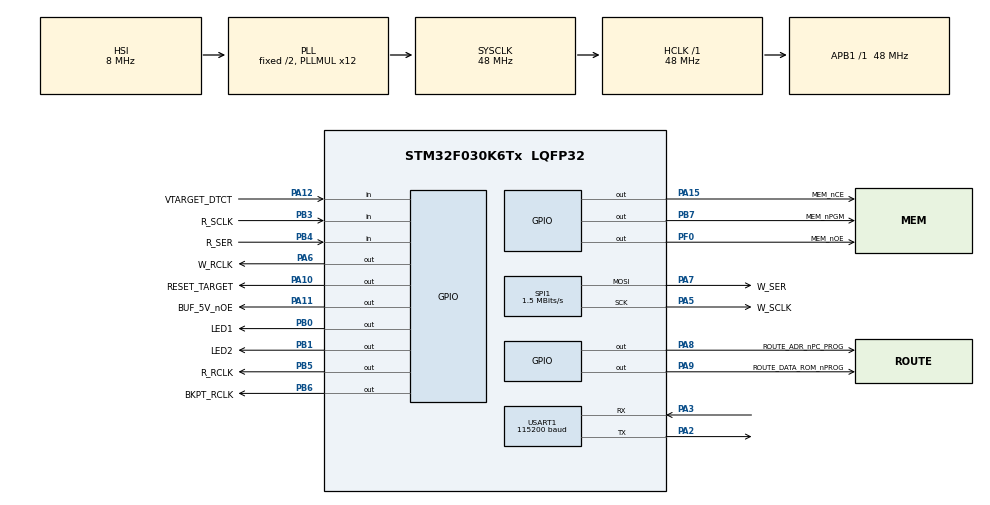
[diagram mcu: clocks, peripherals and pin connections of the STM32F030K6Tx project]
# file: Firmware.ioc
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Mcu.Family=STM32F0
TIM17.Prescaler=48
VP_TIM17_VS_ClockSourceINT.Mode=Enable_Timer
PA7.Mode=TX_Only_Simplex_Unidirect_Master
SPI1.VirtualType=VM_MASTER
USART1.BaudRate=115200
PA9.GPIO_Label=ROUTE_DATA_ROM_nPROG
PA11.GPIO_Label=BUF_5V_nOE
PA6.GPIO_Label=W_RCLK
PB0.GPIO_Label=LED1
PB6.GPIO_Label=BKPT_RCLK
PA12.GPIO_Label=VTARGET_DTCT
RCC.SYSCLKSource=RCC_SYSCLKSOURCE_PLLCLK
ProjectManager.StackSize=0x400
USART1.VirtualMode-Asynchronous=VM_ASYNC
PA3.Mode=Asynchronous
PA13.Signal=SYS_SWDIO
PA15.GPIO_Label=MEM_nCE
PA12.Signal=GPIO_Input
PA8.GPIO_Label=ROUTE_ADR_nPC_PROG
ProjectManager.TargetToolchain=STM32CubeIDE
SPI1.Direction=SPI_DIRECTION_2LINES
RCC.HCLKFreq_Value=48000000
PA9.Signal=GPIO_Output
PB6.Signal=GPIO_Output
SPI1.CalculateBaudRate=1.5 MBits/s
RCC.AHBFreq_Value=48000000
PA5.Signal=SPI1_SCK
PF0-OSC_IN.GPIO_Label=MEM_nOE
board=custom
RCC.PLLMUL=RCC_PLL_MUL12
PB4.GPIO_Label=R_SER
SPI1.Mode=SPI_MODE_MASTER
PA14.Mode=Serial_Wire
PB1.GPIO_Label=LED2
SPI1.DataSize=SPI_DATASIZE_8BIT
PA10.GPIO_Label=RESET_TARGET
PB7.Signal=GPIO_Output
PA8.Signal=GPIO_Output
PA13.Mode=Serial_Wire
Mcu.Name=STM32F030K6Tx
PA2.Signal=USART1_TX
PB7.GPIO_Label=MEM_nPGM
PB3.Signal=GPIO_Input
RCC.SYSCLKFreq_VALUE=48000000
Mcu.Package=LQFP32
PB5.Signal=GPIO_Output
PA6.Signal=GPIO_Output
PB1.Signal=GPIO_Output
PA7.GPIO_Label=W_SER
PA5.GPIO_Label=W_SCLK
PA11.Signal=GPIO_Output
PA10.Signal=GPIO_Output
PA14.Signal=SYS_SWCLK
PA15.Signal=GPIO_Output
ProjectManager.HeapSize=0x200
PB5.GPIO_Label=R_RCLK
RCC.APB1TimFreq_Value=48000000
PA2.Mode=Asynchronous
PF0-OSC_IN.Signal=GPIO_Output
PA11.PinState=GPIO_PIN_SET
RCC.APB1Freq_Value=48000000
SPI1.BaudRatePrescaler=SPI_BAUDRATEPRESCALER_32
PB0.Signal=GPIO_Output
PB4.Signal=GPIO_Input
PA3.Signal=USART1_RX
PA7.Signal=SPI1_MOSI
PA5.Mode=TX_Only_Simplex_Unidirect_Master
PB3.GPIO_Label=R_SCLK

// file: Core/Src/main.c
/* USER CODE BEGIN Header */
/**
 ******************************************************************************
 * @file           : main.c
 * @brief          : Main program body
 ******************************************************************************
 * @attention
 *
 * <h2><center>&copy; Copyright (c) 2021 STMicroelectronics.
 * All rights reserved.</center></h2>
 *
 * This software component is licensed by ST under BSD 3-Clause license,
 * the "License"; You may not use this file except in compliance with the
 * License. You may obtain a copy of the License at:
 *                        opensource.org/licenses/BSD-3-Clause
 *
 ******************************************************************************
 */
/* USER CODE END Header */
#include "main.h"

/* USER CODE BEGIN Includes */
#include "psPROG.h"
/* USER CODE END Includes */

SPI_HandleTypeDef hspi1;

TIM_HandleTypeDef htim17;

UART_HandleTypeDef huart1;

void SystemClock_Config(void);
static void MX_GPIO_Init(void);
static void MX_SPI1_Init(void);
static void MX_USART1_UART_Init(void);
static void MX_TIM17_Init(void);

int main(void)
{

  /* MCU Configuration--------------------------------------------------------*/

  /* Reset of all peripherals, Initializes the Flash interface and the Systick. */
  HAL_Init();

  /* Configure the system clock */
  SystemClock_Config();

  /* Initialize all configured peripherals */
  MX_GPIO_Init();
  MX_SPI1_Init();
  MX_USART1_UART_Init();
  MX_TIM17_Init();

  /* Infinite loop */
  /* USER CODE BEGIN WHILE */

  psPROG(); // Never returns

  while (1) {
    /* USER CODE END WHILE */

  }
}

void SystemClock_Config(void)
{
  RCC_OscInitTypeDef RCC_OscInitStruct = {0};
  RCC_ClkInitTypeDef RCC_ClkInitStruct = {0};
  RCC_PeriphCLKInitTypeDef PeriphClkInit = {0};

  /** Initializes the RCC Oscillators according to the specified parameters
  * in the RCC_OscInitTypeDef structure.
  */
  RCC_OscInitStruct.OscillatorType = RCC_OSCILLATORTYPE_HSI;
  RCC_OscInitStruct.HSIState = RCC_HSI_ON;
  RCC_OscInitStruct.HSICalibrationValue = RCC_HSICALIBRATION_DEFAULT;
  RCC_OscInitStruct.PLL.PLLState = RCC_PLL_ON;
  RCC_OscInitStruct.PLL.PLLSource = RCC_PLLSOURCE_HSI;
  RCC_OscInitStruct.PLL.PLLMUL = RCC_PLL_MUL12;
  RCC_OscInitStruct.PLL.PREDIV = RCC_PREDIV_DIV1;
  if (HAL_RCC_OscConfig(&RCC_OscInitStruct) != HAL_OK)
  {
    Error_Handler();
  }
  /** Initializes the CPU, AHB and APB buses clocks
  */
  RCC_ClkInitStruct.ClockType = RCC_CLOCKTYPE_HCLK|RCC_CLOCKTYPE_SYSCLK
                              |RCC_CLOCKTYPE_PCLK1;
  RCC_ClkInitStruct.SYSCLKSource = RCC_SYSCLKSOURCE_PLLCLK;
  RCC_ClkInitStruct.AHBCLKDivider = RCC_SYSCLK_DIV1;
  RCC_ClkInitStruct.APB1CLKDivider = RCC_HCLK_DIV1;

  if (HAL_RCC_ClockConfig(&RCC_ClkInitStruct, FLASH_LATENCY_1) != HAL_OK)
  {
    Error_Handler();
  }
  PeriphClkInit.PeriphClockSelection = RCC_PERIPHCLK_USART1;
  PeriphClkInit.Usart1ClockSelection = RCC_USART1CLKSOURCE_PCLK1;
  if (HAL_RCCEx_PeriphCLKConfig(&PeriphClkInit) != HAL_OK)
  {
    Error_Handler();
  }
}

static void MX_SPI1_Init(void)
{

  /* SPI1 parameter configuration*/
  hspi1.Instance = SPI1;
  hspi1.Init.Mode = SPI_MODE_MASTER;
  hspi1.Init.Direction = SPI_DIRECTION_2LINES;
  hspi1.Init.DataSize = SPI_DATASIZE_8BIT;
  hspi1.Init.CLKPolarity = SPI_POLARITY_LOW;
  hspi1.Init.CLKPhase = SPI_PHASE_1EDGE;
  hspi1.Init.NSS = SPI_NSS_SOFT;
  hspi1.Init.BaudRatePrescaler = SPI_BAUDRATEPRESCALER_32;
  hspi1.Init.FirstBit = SPI_FIRSTBIT_MSB;
  hspi1.Init.TIMode = SPI_TIMODE_DISABLE;
  hspi1.Init.CRCCalculation = SPI_CRCCALCULATION_DISABLE;
  hspi1.Init.CRCPolynomial = 7;
  hspi1.Init.CRCLength = SPI_CRC_LENGTH_DATASIZE;
  hspi1.Init.NSSPMode = SPI_NSS_PULSE_ENABLE;
  if (HAL_SPI_Init(&hspi1) != HAL_OK)
  {
    Error_Handler();
  }

}

static void MX_TIM17_Init(void)
{

  htim17.Instance = TIM17;
  htim17.Init.Prescaler = 48;
  htim17.Init.CounterMode = TIM_COUNTERMODE_UP;
  htim17.Init.Period = 65535;
  htim17.Init.ClockDivision = TIM_CLOCKDIVISION_DIV1;
  htim17.Init.RepetitionCounter = 0;
  htim17.Init.AutoReloadPreload = TIM_AUTORELOAD_PRELOAD_DISABLE;
  if (HAL_TIM_Base_Init(&htim17) != HAL_OK)
  {
    Error_Handler();
  }
  /* USER CODE BEGIN TIM17_Init 2 */
  HAL_TIM_Base_Start(&htim17);

  /* USER CODE END TIM17_Init 2 */

}

static void MX_USART1_UART_Init(void)
{

  huart1.Instance = USART1;
  huart1.Init.BaudRate = 115200;
  huart1.Init.WordLength = UART_WORDLENGTH_8B;
  huart1.Init.StopBits = UART_STOPBITS_1;
  huart1.Init.Parity = UART_PARITY_NONE;
  huart1.Init.Mode = UART_MODE_TX_RX;
  huart1.Init.HwFlowCtl = UART_HWCONTROL_NONE;
  huart1.Init.OverSampling = UART_OVERSAMPLING_16;
  huart1.Init.OneBitSampling = UART_ONE_BIT_SAMPLE_DISABLE;
  huart1.AdvancedInit.AdvFeatureInit = UART_ADVFEATURE_NO_INIT;
  if (HAL_UART_Init(&huart1) != HAL_OK)
  {
    Error_Handler();
  }

}

static void MX_GPIO_Init(void)
{
  GPIO_InitTypeDef GPIO_InitStruct = {0};

  /* GPIO Ports Clock Enable */
  __HAL_RCC_GPIOF_CLK_ENABLE();
  __HAL_RCC_GPIOA_CLK_ENABLE();
  __HAL_RCC_GPIOB_CLK_ENABLE();

  /*Configure GPIO pin Output Level */
  HAL_GPIO_WritePin(MEM_nOE_GPIO_Port, MEM_nOE_Pin, GPIO_PIN_RESET);

  /*Configure GPIO pin Output Level */
  HAL_GPIO_WritePin(GPIOA, W_RCLK_Pin|ROUTE_ADR_nPC_PROG_Pin|ROUTE_DATA_ROM_nPROG_Pin|RESET_TARGET_Pin
                          |MEM_nCE_Pin, GPIO_PIN_RESET);

  /*Configure GPIO pin Output Level */
  HAL_GPIO_WritePin(GPIOB, LED1_Pin|LED2_Pin|R_RCLK_Pin|BKPT_RCLK_Pin
                          |MEM_nPGM_Pin, GPIO_PIN_RESET);

  /*Configure GPIO pin Output Level */
  HAL_GPIO_WritePin(BUF_5V_nOE_GPIO_Port, BUF_5V_nOE_Pin, GPIO_PIN_SET);

  /*Configure GPIO pin : MEM_nOE_Pin */
  GPIO_InitStruct.Pin = MEM_nOE_Pin;
  GPIO_InitStruct.Mode = GPIO_MODE_OUTPUT_PP;
  GPIO_InitStruct.Pull = GPIO_NOPULL;
  GPIO_InitStruct.Speed = GPIO_SPEED_FREQ_LOW;
  HAL_GPIO_Init(MEM_nOE_GPIO_Port, &GPIO_InitStruct);

  /*Configure GPIO pins : W_RCLK_Pin ROUTE_ADR_nPC_PROG_Pin ROUTE_DATA_ROM_nPROG_Pin RESET_TARGET_Pin
                           BUF_5V_nOE_Pin MEM_nCE_Pin */
  GPIO_InitStruct.Pin = W_RCLK_Pin|ROUTE_ADR_nPC_PROG_Pin|ROUTE_DATA_ROM_nPROG_Pin|RESET_TARGET_Pin
                          |BUF_5V_nOE_Pin|MEM_nCE_Pin;
  GPIO_InitStruct.Mode = GPIO_MODE_OUTPUT_PP;
  GPIO_InitStruct.Pull = GPIO_NOPULL;
  GPIO_InitStruct.Speed = GPIO_SPEED_FREQ_LOW;
  HAL_GPIO_Init(GPIOA, &GPIO_InitStruct);

  /*Configure GPIO pins : LED1_Pin LED2_Pin R_RCLK_Pin BKPT_RCLK_Pin
                           MEM_nPGM_Pin */
  GPIO_InitStruct.Pin = LED1_Pin|LED2_Pin|R_RCLK_Pin|BKPT_RCLK_Pin
                          |MEM_nPGM_Pin;
  GPIO_InitStruct.Mode = GPIO_MODE_OUTPUT_PP;
  GPIO_InitStruct.Pull = GPIO_NOPULL;
  GPIO_InitStruct.Speed = GPIO_SPEED_FREQ_LOW;
  HAL_GPIO_Init(GPIOB, &GPIO_InitStruct);

  /*Configure GPIO pin : VTARGET_DTCT_Pin */
  GPIO_InitStruct.Pin = VTARGET_DTCT_Pin;
  GPIO_InitStruct.Mode = GPIO_MODE_INPUT;
  GPIO_InitStruct.Pull = GPIO_NOPULL;
  HAL_GPIO_Init(VTARGET_DTCT_GPIO_Port, &GPIO_InitStruct);

  /*Configure GPIO pins : R_SCLK_Pin R_SER_Pin */
  GPIO_InitStruct.Pin = R_SCLK_Pin|R_SER_Pin;
  GPIO_InitStruct.Mode = GPIO_MODE_INPUT;
  GPIO_InitStruct.Pull = GPIO_NOPULL;
  HAL_GPIO_Init(GPIOB, &GPIO_InitStruct);

}

void Error_Handler(void)
{
  __disable_irq();
  while (1) {
  }
}

#ifdef  USE_FULL_ASSERT
/**
  * @brief  Reports the name of the source file and the source line number
  *         where the assert_param error has occurred.
  * @param  file: pointer to the source file name
  * @param  line: assert_param error line source number
  * @retval None
  */
void assert_failed(uint8_t *file, uint32_t line)
{
  /* USER CODE BEGIN 6 */
  /* User can add his own implementation to report the file name and line
     number,
     ex: printf("Wrong parameters value: file %s on line %d\r\n", file, line) */
  /* USER CODE END 6 */
}
#endif /* USE_FULL_ASSERT */

/************************ (C) COPYRIGHT STMicroelectronics *****END OF FILE****/
